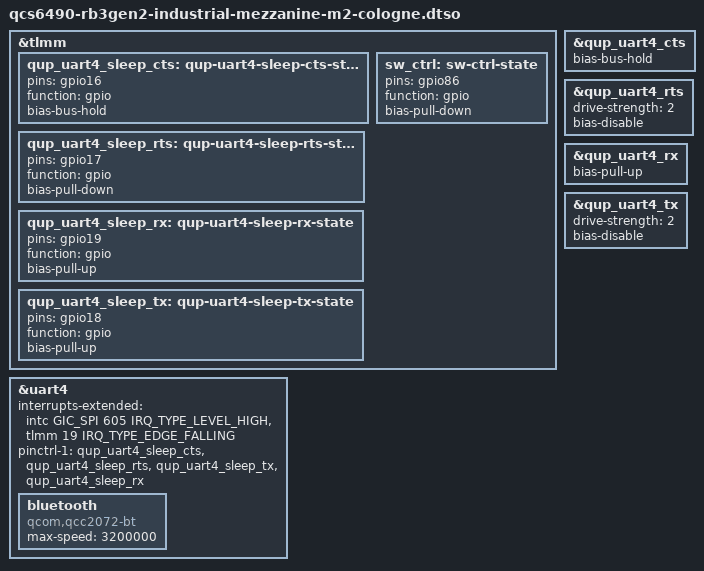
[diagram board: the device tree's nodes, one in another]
// SPDX-License-Identifier: BSD-3-Clause
/*
 * Copyright (c) 2026, Qualcomm Innovation Center, Inc. All rights reserved.
*/

/dts-v1/;
/plugin/;
#include <dt-bindings/interrupt-controller/arm-gic.h>

&tlmm {
	qup_uart4_sleep_cts: qup-uart4-sleep-cts-state {
		pins = "gpio16";
		function = "gpio";
		/*
		 * Configure a bias-bus-hold on CTS to lower power
		 * usage when Bluetooth is turned off. Bus hold will
		 * maintain a low power state regardless of whether
		 * the Bluetooth module drives the pin in either
		 * direction or leaves the pin fully unpowered.
		 */
		bias-bus-hold;
	};

	qup_uart4_sleep_rts: qup-uart4-sleep-rts-state {
		pins = "gpio17";
		function = "gpio";
		/*
		 * Configure pull-down on RTS. As RTS is active low
		 * signal, pull it low to indicate the BT SoC that it
		 * can wakeup the system anytime from suspend state by
		 * pulling RX low (by sending wakeup bytes).
		 */
		bias-pull-down;
	};

	qup_uart4_sleep_rx: qup-uart4-sleep-rx-state {
		pins = "gpio19";
		function = "gpio";
		/*
		 * Configure a pull-up on RX. This is needed to avoid
		 * garbage data when the TX pin of the Bluetooth module
		 * is floating which may cause spurious wakeups.
		 */
		bias-pull-up;
	};

	qup_uart4_sleep_tx: qup-uart4-sleep-tx-state {
		pins = "gpio18";
		function = "gpio";
		/*
		 * Configure pull-up on TX when it isn't actively driven
		 * to prevent BT SoC from receiving garbage during sleep.
		 */
		bias-pull-up;
	};

	sw_ctrl: sw-ctrl-state {
		pins = "gpio86";
		function = "gpio";
		bias-pull-down;
	};
};

&qup_uart4_cts {
	/*
	 * Configure a bias-bus-hold on CTS to lower power
	 * usage when Bluetooth is turned off. Bus hold will
	 * maintain a low power state regardless of whether
	 * the Bluetooth module drives the pin in either
	 * direction or leaves the pin fully unpowered.
	 */
	bias-bus-hold;
};

&qup_uart4_rts {
	/* We'll drive RTS, so no pull */
	drive-strength = <2>;
	bias-disable;
};

&qup_uart4_rx {
	/*
	 * Configure a pull-up on RX. This is needed to avoid
	 * garbage data when the TX pin of the Bluetooth module is
	 * in tri-state (module powered off or not driving the
	 * signal yet).
	 */
	bias-pull-up;
};

&qup_uart4_tx {
	/* We'll drive TX, so no pull */
	drive-strength = <2>;
	bias-disable;
};

&uart4 {
	status = "okay";
	/delete-property/ interrupts;
	interrupts-extended = <&intc GIC_SPI 605 IRQ_TYPE_LEVEL_HIGH>,
				<&tlmm 19 IRQ_TYPE_EDGE_FALLING>;
	pinctrl-names = "default", "sleep";
	pinctrl-1 = <&qup_uart4_sleep_cts>, <&qup_uart4_sleep_rts>,
			<&qup_uart4_sleep_tx>, <&qup_uart4_sleep_rx>;

	bluetooth: bluetooth {
		compatible = "qcom,qcc2072-bt";
		max-speed = <3200000>;
	};
};
